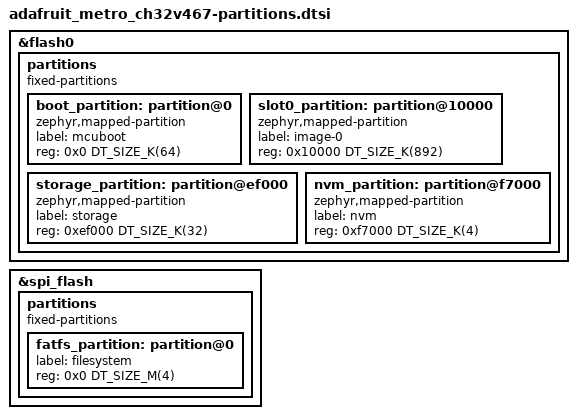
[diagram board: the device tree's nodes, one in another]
/* Partition layout for adafruit_metro_ch32v467: the flash memory map shared by the
 * bootloader and every application image. Generated by
 * tools/partition_layout.py; do not edit by hand -- re-run
 * `python3 tools/partition_layout.py --fix adafruit_metro_ch32v467` after changing
 * the upstream board geometry or tools/boards.toml.
 *
 * Board-specific overlay glue (delete-nodes, device enablement,
 * aliases/chosen) lives in dts/adafruit/adafruit_metro_ch32v467.dtsi, which includes
 * this file.
 */

&flash0 {
	partitions {
		compatible = "fixed-partitions";
		#address-cells = <1>;
		#size-cells = <1>;
		ranges;

		boot_partition: partition@0 {
			compatible = "zephyr,mapped-partition";
			label = "mcuboot";
			reg = <0x0 DT_SIZE_K(64)>;
		};

		slot0_partition: partition@10000 {
			compatible = "zephyr,mapped-partition";
			label = "image-0";
			reg = <0x10000 DT_SIZE_K(892)>;
		};

		storage_partition: partition@ef000 {
			compatible = "zephyr,mapped-partition";
			label = "storage";
			reg = <0xef000 DT_SIZE_K(32)>;
		};

		nvm_partition: partition@f7000 {
			compatible = "zephyr,mapped-partition";
			label = "nvm";
			reg = <0xf7000 DT_SIZE_K(4)>;
		};
	};
};

&spi_flash {
	partitions {
		compatible = "fixed-partitions";
		#address-cells = <1>;
		#size-cells = <1>;

		fatfs_partition: partition@0 {
			label = "filesystem";
			reg = <0x0 DT_SIZE_M(4)>;
		};
	};
};
